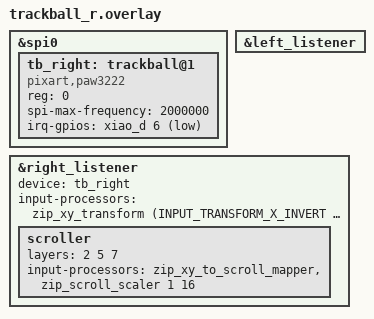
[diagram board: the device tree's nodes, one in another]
#include <dt-bindings/zmk/input_transform.h>
#include "lism.dtsi"

&spi0 {
    status = "okay";

    tb_right: trackball@1 {
        status = "okay";
        compatible = "pixart,paw3222";
        reg = <0>;
        spi-max-frequency = <2000000>;
        irq-gpios = <&xiao_d 6 (GPIO_ACTIVE_LOW | GPIO_PULL_UP)>;
    };
};

// 左（split経由）のリスナーを有効化
&left_listener {
    status = "okay";
};

// 右（中央直結）のリスナーを有効化し、deviceを紐付け
&right_listener {
    status = "okay";
    device = <&tb_right>;
    input-processors = 
        <&zip_xy_transform (INPUT_TRANSFORM_X_INVERT | INPUT_TRANSFORM_Y_INVERT)>;

    scroller {
        layers = <2 5 7>;
        input-processors = 
            <&zip_xy_to_scroll_mapper>,
            <&zip_scroll_scaler 1 16>;
    };
};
